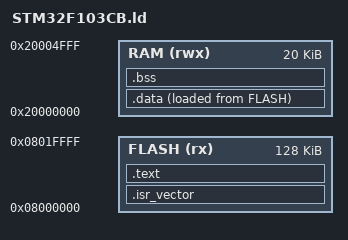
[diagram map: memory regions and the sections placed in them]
/* STM32F103CB: 128K flash, 20K RAM (matches Keil scatter 0x20000) */
MEMORY
{
  FLASH (rx) : ORIGIN = 0x08000000, LENGTH = 128K
  RAM (rwx)  : ORIGIN = 0x20000000, LENGTH = 20K
}

_estack = ORIGIN(RAM) + LENGTH(RAM);

SECTIONS
{
  .isr_vector :
  {
    KEEP(*(.isr_vector))
  } > FLASH

  .text :
  {
    *(.text*)
    *(.rodata*)
    KEEP(*(.init))
    KEEP(*(.fini))
    _etext = .;
  } > FLASH

  _sidata = LOADADDR(.data);

  .data :
  {
    _sdata = .;
    *(.data*)
    _edata = .;
  } > RAM AT > FLASH

  .bss :
  {
    _sbss = .;
    *(.bss*)
    *(COMMON)
    _ebss = .;
  } > RAM

  end = .;
  _end = .;
}
